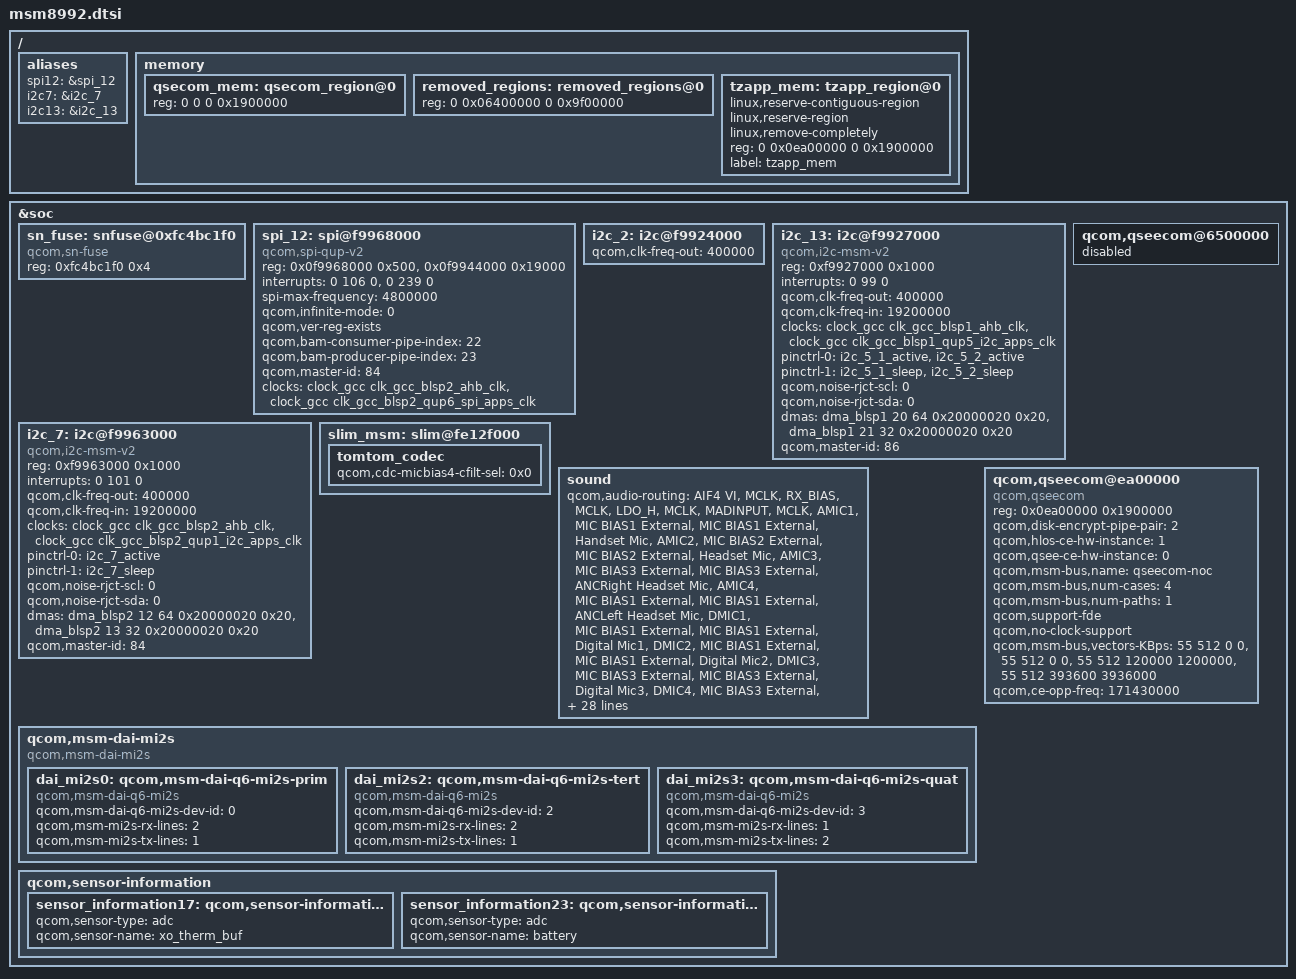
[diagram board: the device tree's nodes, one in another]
/* Copyright (c) 2013-2015, The Linux Foundation. All rights reserved.
 * Copyright (C) 2016 XiaoMi, Inc.
 * Modified by Ketut Putu Kumajaya, 2016
 *
 * This program is free software; you can redistribute it and/or modify
 * it under the terms of the GNU General Public License version 2 and
 * only version 2 as published by the Free Software Foundation.
 *
 * This program is distributed in the hope that it will be useful,
 * but WITHOUT ANY WARRANTY; without even the implied warranty of
 * MERCHANTABILITY or FITNESS FOR A PARTICULAR PURPOSE.  See the
 * GNU General Public License for more details.
 */

#include "../msm8992.dtsi"

/ {
	aliases {
		spi12 = &spi_12;
		i2c7 = &i2c_7;
		i2c13 = &i2c_13;
	};

	memory {
		qsecom_mem: qsecom_region@0 {
			reg = <0 0 0 0x1900000>;
		};

		removed_regions: removed_regions@0 {
			reg = <0 0x06400000 0 0x9f00000>;
		};

		tzapp_mem: tzapp_region@0 {
			linux,reserve-contiguous-region;
			linux,reserve-region;
			linux,remove-completely;
			reg = <0 0x0ea00000 0 0x1900000>;
			label = "tzapp_mem";
		};
	};
};

&soc {
	sn_fuse: snfuse@0xfc4bc1f0 {
		compatible = "qcom,sn-fuse";
		reg = <0xfc4bc1f0 0x4>;
		reg-names = "sn-base";
	};

	spi_12: spi@f9968000 { /* SPI : BLSP12(BLSP2 QUP5) */
		compatible = "qcom,spi-qup-v2";
		#address-cells = <1>;
		#size-cells = <0>;
		reg-names = "spi_physical", "spi_bam_physical";
		reg = <0x0f9968000 0x500>,
		      <0x0f9944000 0x19000>;
		interrupt-names = "spi_irq", "spi_bam_irq";
		interrupts = <0 106 0>, <0 239 0>;
		spi-max-frequency = <4800000>;
		qcom,infinite-mode = <0>;
		qcom,ver-reg-exists;
		qcom,bam-consumer-pipe-index = <22>;
		qcom,bam-producer-pipe-index = <23>;
		qcom,master-id = <84>;

		clock-names = "iface_clk", "core_clk";

		clocks = <&clock_gcc clk_gcc_blsp2_ahb_clk>,
			 <&clock_gcc clk_gcc_blsp2_qup6_spi_apps_clk>;
	};

	i2c_2: i2c@f9924000 { /* BLSP1 QUP2 */
		qcom,clk-freq-out = <400000>;
	};

	i2c_13: i2c@f9927000 { /* BLSP5 from (1~12) point view*/
		compatible = "qcom,i2c-msm-v2";
		#address-cells = <1>;
		#size-cells = <0>;
		reg-names = "qup_phys_addr";
		reg = <0xf9927000 0x1000>;
		interrupt-names = "qup_irq";
		interrupts = <0 99 0>;
		qcom,clk-freq-out = <400000>;
		qcom,clk-freq-in  = <19200000>;
		clock-names = "iface_clk", "core_clk";
		clocks = <&clock_gcc clk_gcc_blsp1_ahb_clk>,
			<&clock_gcc clk_gcc_blsp1_qup5_i2c_apps_clk>;

		pinctrl-names = "i2c_active", "i2c_sleep";
		pinctrl-0 = <&i2c_5_1_active &i2c_5_2_active>;
		pinctrl-1 = <&i2c_5_1_sleep &i2c_5_2_sleep>;
		qcom,noise-rjct-scl = <0>;
		qcom,noise-rjct-sda = <0>;
		dmas = <&dma_blsp1 20 64 0x20000020 0x20>,
			<&dma_blsp1 21 32 0x20000020 0x20>;
		dma-names = "tx", "rx";
		qcom,master-id = <86>;
	};

	i2c_7: i2c@f9963000 { /* BLSP7 from (1~12) point view*/
		compatible = "qcom,i2c-msm-v2";
		#address-cells = <1>;
		#size-cells = <0>;
		reg-names = "qup_phys_addr";
		reg = <0xf9963000 0x1000>;
		interrupt-names = "qup_irq";
		interrupts = <0 101 0>;
		qcom,clk-freq-out = <400000>;
		qcom,clk-freq-in  = <19200000>;
		clock-names = "iface_clk", "core_clk";
		clocks = <&clock_gcc clk_gcc_blsp2_ahb_clk>,
			<&clock_gcc clk_gcc_blsp2_qup1_i2c_apps_clk>;

		pinctrl-names = "i2c_active", "i2c_sleep";
		pinctrl-0 = <&i2c_7_active>;
		pinctrl-1 = <&i2c_7_sleep>;
		qcom,noise-rjct-scl = <0>;
		qcom,noise-rjct-sda = <0>;
		dmas = <&dma_blsp2 12 64 0x20000020 0x20>,
			<&dma_blsp2 13 32 0x20000020 0x20>;
		dma-names = "tx", "rx";
		qcom,master-id = <84>;
	};

	slim_msm: slim@fe12f000 {
		tomtom_codec {
			qcom,cdc-micbias4-cfilt-sel = <0x0>;
		};
	};

	sound {
		qcom,audio-routing =
			"AIF4 VI", "MCLK",
			"RX_BIAS", "MCLK",
			"LDO_H", "MCLK",
			"MADINPUT", "MCLK",
			"AMIC1", "MIC BIAS1 External",
			"MIC BIAS1 External", "Handset Mic",
			"AMIC2", "MIC BIAS2 External",
			"MIC BIAS2 External", "Headset Mic",
			"AMIC3", "MIC BIAS3 External",
			"MIC BIAS3 External", "ANCRight Headset Mic",
			"AMIC4", "MIC BIAS1 External",
			"MIC BIAS1 External", "ANCLeft Headset Mic",
			"DMIC1", "MIC BIAS1 External",
			"MIC BIAS1 External", "Digital Mic1",
			"DMIC2", "MIC BIAS1 External",
			"MIC BIAS1 External", "Digital Mic2",
			"DMIC3", "MIC BIAS3 External",
			"MIC BIAS3 External", "Digital Mic3",
			"DMIC4", "MIC BIAS3 External",
			"MIC BIAS3 External", "Digital Mic4",
			"DMIC5", "MIC BIAS4 External",
			"MIC BIAS4 External", "Digital Mic5",
			"DMIC6", "MIC BIAS4 External",
			"MIC BIAS4 External", "Digital Mic6";

		asoc-cpu = <&dai_pri_auxpcm>, <&dai_sec_auxpcm>, <&dai_hdmi>, <&dai_mi2s0>,
				<&dai_mi2s2>, <&dai_mi2s3>,
				<&sb_0_rx>, <&sb_0_tx>, <&sb_1_rx>, <&sb_1_tx>,
				<&sb_2_rx>, <&sb_2_tx>, <&sb_3_rx>, <&sb_3_tx>,
				<&sb_4_rx>, <&sb_4_tx>, <&sb_5_tx>, <&bt_sco_rx>,
				<&bt_sco_tx>, <&int_fm_rx>, <&int_fm_tx>, <&afe_pcm_rx>,
				<&afe_pcm_tx>, <&afe_proxy_rx>, <&afe_proxy_tx>,
				<&incall_record_rx>, <&incall_record_tx>, <&incall_music_rx>,
				<&incall_music2_rx>;
		asoc-cpu-names = "msm-dai-q6-auxpcm.1", "msm-dai-q6-auxpcm.2",
				"msm-dai-q6-hdmi.8", "msm-dai-q6-mi2s.0",
				"msm-dai-q6-mi2s.2", "msm-dai-q6-mi2s.3",
				"msm-dai-q6-dev.16384", "msm-dai-q6-dev.16385",
				"msm-dai-q6-dev.16386", "msm-dai-q6-dev.16387",
				"msm-dai-q6-dev.16388", "msm-dai-q6-dev.16389",
				"msm-dai-q6-dev.16390", "msm-dai-q6-dev.16391",
				"msm-dai-q6-dev.16392", "msm-dai-q6-dev.16393",
				"msm-dai-q6-dev.16395", "msm-dai-q6-dev.12288",
				"msm-dai-q6-dev.12289", "msm-dai-q6-dev.12292",
				"msm-dai-q6-dev.12293", "msm-dai-q6-dev.224",
				"msm-dai-q6-dev.225", "msm-dai-q6-dev.241",
				"msm-dai-q6-dev.240", "msm-dai-q6-dev.32771",
				"msm-dai-q6-dev.32772", "msm-dai-q6-dev.32773",
				"msm-dai-q6-dev.32770";
	};

	qcom,msm-dai-mi2s {
		compatible = "qcom,msm-dai-mi2s";
		dai_mi2s0: qcom,msm-dai-q6-mi2s-prim {
			compatible = "qcom,msm-dai-q6-mi2s";
			qcom,msm-dai-q6-mi2s-dev-id = <0>;
			qcom,msm-mi2s-rx-lines = <2>;
			qcom,msm-mi2s-tx-lines = <1>;
		};
		dai_mi2s2: qcom,msm-dai-q6-mi2s-tert {
			compatible = "qcom,msm-dai-q6-mi2s";
			qcom,msm-dai-q6-mi2s-dev-id = <2>;
			qcom,msm-mi2s-rx-lines = <2>;
			qcom,msm-mi2s-tx-lines = <1>;
		};
		dai_mi2s3: qcom,msm-dai-q6-mi2s-quat {
			compatible = "qcom,msm-dai-q6-mi2s";
			qcom,msm-dai-q6-mi2s-dev-id = <3>;
			qcom,msm-mi2s-rx-lines = <1>;
			qcom,msm-mi2s-tx-lines = <2>;
		};
	};

	qcom,qseecom@6500000 {
		status = "disabled";
	};

	qcom,qseecom@ea00000 {
		compatible = "qcom,qseecom";
		reg = <0x0ea00000 0x1900000>;
		reg-names = "secapp-region";
		qcom,disk-encrypt-pipe-pair = <2>;
		qcom,hlos-ce-hw-instance = <1>;
		qcom,qsee-ce-hw-instance = <0>;
		qcom,msm-bus,name = "qseecom-noc";
		qcom,msm-bus,num-cases = <4>;
		qcom,msm-bus,num-paths = <1>;
		qcom,support-fde;
		qcom,no-clock-support;
		qcom,msm-bus,vectors-KBps =
				<55 512 0 0>,
				<55 512 0 0>,
				<55 512 120000 1200000>,
				<55 512 393600 3936000>;
		qcom,ce-opp-freq = <171430000>;
	};

	qcom,sensor-information {
		sensor_information17: qcom,sensor-information@17 {
			qcom,sensor-type =  "adc";
			qcom,sensor-name = "xo_therm_buf";
		};

		sensor_information23: qcom,sensor-information-23 {
			qcom,sensor-type =  "adc";
			qcom,sensor-name = "battery";
		};
	};
};

#include "msm-pm8994.dtsi"
#include "msm-pmi8994.dtsi"

